# MMC register map
Vendor: Texas Instruments
Registers are 32-bit, access per field, reset 0x0 unless marked. A register's access mark holds for its fields unless they carry their own. Offsets are as the file gives them; [hi:lo] are bit positions; 'fields as' and 'values as' point back to an identical list.

## MMC (part 2 of 2)
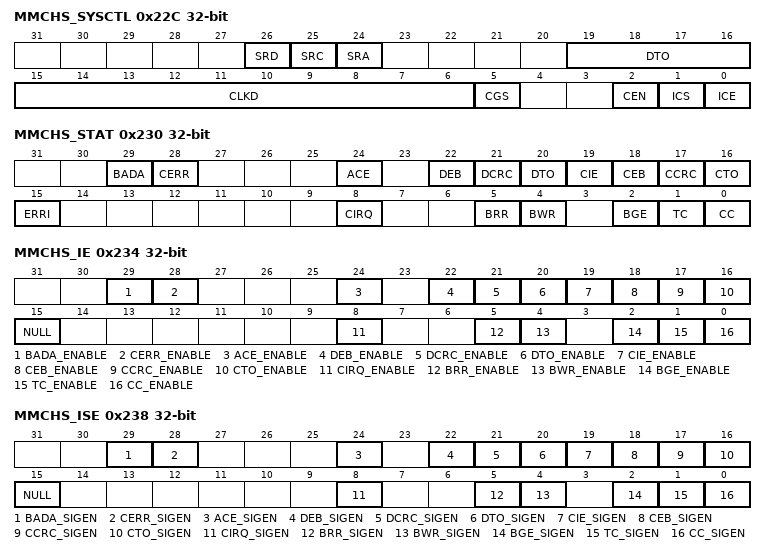
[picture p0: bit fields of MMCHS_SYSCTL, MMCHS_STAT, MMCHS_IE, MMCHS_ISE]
0x22C MMCHS_SYSCTL — SD System Control Register This register defines the system controls to set software resets, clock frequency management and data timeout. [31:24] = Software resets [23:16] = Timeout control [15:0] = Clock control
  [26] SRD rw — Software reset for DAT line This bit is set to 1 for reset and released to 0 when completed. For more information about SRD bit manipulation, see . DAT finite state machine in both clock domain are also reset. Here below are the registers cleared by MMCHS_SYSCTL[SRD]: - MMCHS_DATA - MMCHS_PSTATE: BRE, BWE, RTA, WTA, DLA and DATI - MMCHS_HCTL: SBGR and CR - MMCHS_STAT: BRR, BWR, BGE and TC Interconnect and SDIO buffer data management is reinitialized.
    0=Work (Reset completed); 1=Reset (Software reset for DAT line)
  [25] SRC rw — Software reset for CMD line For more information about SRC bit manipulation, see . This bit is set to 1 for reset and released to 0 when completed. CMD finite state machine in both clock domain are also reset. Here below the registers cleared by MMCHS_SYSCTL[SRC]: - MMCHS_PSTATE: CMDI - MMCHS_STAT: CC Interconnect and SDIO command status management is reinitialized.
    0=Work (Reset completed); 1=Reset (Software reset for CMD line)
  [24] SRA rw — Software reset for all This bit is set to 1 for reset , and released to 0 when completed. This reset affects the entire host controller except for the capabilities registers (MMCHS_CAPA and MMCHS_CUR_CAPA).
    0=Work (Reset completed); 1=Reset (Software reset for all the design)
  [19:16] DTO rw — Data timeout counter value and busy timeout. This value determines the interval by which DAT lines timeouts are detected. The host driver needs to set this bitfield based on - the maximum read access time (NAC) (Refer to the SD Specification Part1 Physical Layer), - the data read access time values (TAAC and NSAC) in the card specific data register (CSD) of the card, - the timeout clock base frequency (MMCHS_CAPA[TCF]). If the card does not respond within the specified number of cycles, a data timeout error occurs (MMCHS_STA[DTO]). The MMCHS_SYSCTL[DTO] register is also used to check busy duration, to generate busy timeout for commands with busy response or for busy programming during a write command. Timeout on CRC status is generated if no CRC token is present after a block write.
    0=1stDTO (TCF x 2^13); 1=2ndDTO (TCF x 2^14); 14=15thDTO (TCF x 2^27)
  [15:6] CLKD rw — Clock frequency select These bits define the ratio between MMC_FCLK and the output clock frequency on the mmc_clk pin.
    0=Div1023 (MMC_FCLK bypass); 1=Bypass0 (MMC_FCLK bypass); 2=Bypass1 (MMC_FCLK / 2); 3=Div3 (MMC_FCLK / 3); 0x3FF=Div2 (MMC_FCLK / 1023)
  [5] CGS ro — Clock Generator Select - For SD cards Host Controller Version 3.00 supports this bit. This bit is used to select the clock generator mode in MMCHS_SYSCTL[15:6] CLKD. If the Programmable Clock Mode is supported (non-zero value is set to MMCHS_CAPA2[23:16] CM), this bit attribute is RW, and if not supported, this bit attribute is RO and zero is read. This bit depends on the setting of MMCHS_AC12[31] PV_ENABLE. If PV_ENABLE = 0, this bit is set by Host Driver. If PV_ENABLE = 1, this bit is automatically set to a value specified in one of Preset Value registers, see, .
  [2] CEN rw — Clock enable This bit controls if the clock is provided to the card or not.
    0=Disable (The clock is not provided to the card . Clock frequency can be changed .); 1=Enable (The clock is provided to the card and can be automatically gated when[AUTOIDLE] is set to 1 (default value) . The host driver shall wait to set this bit to 1 until the Internal clock is stable ([ICS]).)
  [1] ICS ro — Internal clock stable (status) This bit indicates either the internal clock is stable or not.
    1=Ready (The internal clock is stable after enabling the clock ([ICE]) or after changing the clock ratio ([CLKD]).); 0=NotReady (The internal clock is not stable.)
  [0] ICE rw — Internal clock enable This register controls the internal clock activity. In very low power state, the internal clock is stopped. Note: The activity of the debounce clock (used for wakeup events) and the interface clock (used for reads and writes to the module register map) are not affected by this register.
    0=Stop (The internal clock is stopped (very low power state).); 1=Oscillate (The internal clock oscillates and can be automatically gated when[AUTOIDLE] is set to 1 (default value) .)
0x230 MMCHS_STAT — Interrupt Status Register The interrupt status regroups all the status of the module internal events that can generate an interrupt. [31:16] = Error Interrupt Status [15:0] = Normal Interrupt Status
  [29] BADA rw — Bad access to data space This bit is set automatically to indicate a bad access to buffer when not allowed: -This bit is set during a read access to the data register (MMCHS_DATA) while buffer reads are not allowed (MMCHS_PSTATE[BRE] =0) -This bit is set during a write access to the data register (MMCHS_DATA) while buffer writes are not allowed (MMCHS_STATE[BWE] =0)
    0=St_un_w (Status bit unchanged); 1=St_rst_w (Status is cleared); 1=IRQ_tru_r (Bad Access); 0=IRQ_fal_r (No Interrupt.)
  [28] CERR rw — Card error This bit is set automatically when there is at least one error in a response of type R1, R1b, R6, R5 or R5b. Only bits referenced as type E(error) in status field in the response can set a card status error. An error bit in the response is flagged only if corresponding bit in card status response error MMCHS_CSRE in set. There is no card error detection for autoCMD12 command. The host driver shall read MMCHS_RSP76 register to detect error bits in the command response.
    0=St_un_w (Status bit unchanged); 1=St_rst_w (Status is cleared); 1=IRQ_tru_r (Card error); 0=IRQ_fal_r (No Error)
  [24] ACE rw — Auto CMD error Auto CMD12 uses this error status. This bit is set when detecting that one of the bits D00-D04 in Auto CMD Error Status register (MMCHS_AC12) has changed from 0 to 1. In case of Auto CMD12, this bit is set to 1, not only when the errors in Auto CMD12 occur but also when Auto CMD12 is not executed due to the previous command error.
    0=St_un_w (Status bit unchanged); 1=St_rst_w (Status is cleared); 1=IRQ_tru_r (Auto CMD error); 0=IRQ_fal_r (No Error.)
  [22] DEB rw — Data End Bit error This bit is set automatically when detecting a 0 at the end bit position of read data on DAT line or at the end position of the CRC status in write mode.
    0=St_un_w (Status bit unchanged); 1=St_rst_w (Status is cleared); 1=IRQ_tru_r (Data end bit error); 0=IRQ_fal_r (No Error)
  [21] DCRC rw — Data CRC Error This bit is set automatically when there is a CRC16 error in the data phase response following a block read command or if there is a 3-bit CRC status different of a position '010' token during a block write command.
    0=St_un_w (Status bit unchanged); 1=St_rst_w (Status is cleared); 1=IRQ_tru_r (Data CRC error); 0=IRQ_fal_r (No Error.)
  [20] DTO rw — Data timeout error This bit is set automatically according to the following conditions: - busy timeout for R1b, R5b response type - busy timeout after write CRC status - write CRC status timeout - read data timeout
    0=St_un_w (Status bit unchanged); 1=St_rst_w (Status is cleared); 1=IRQ_tru_r (Time out); 0=IRQ_fal_r (No error.)
  [19] CIE rw — Command index error This bit is set automatically when response index differs from corresponding command index previously emitted. It depends on the enable in MMCHS_CMD[CICE] register.
    0=St_un_w (Status bit unchanged); 1=St_rst_w (Status is cleared); 1=IRQ_tru_r (Command index error); 0=IRQ_fal_r (No error.)
  [18] CEB rw — Command end bit error This bit is set automatically when detecting a 0 at the end bit position of a command response.
    0=St_un_w (Status bit unchanged); 1=St_rst_w (Status is cleared); 1=IRQ_tru_r (Command end bit error); 0=IRQ_fal_r (No error.)
  [17] CCRC rw — Command CRC Error This bit is set automatically when there is a CRC7 error in the command response depending on the enable in MMCHS_CMD[CCCE] register.
    0=St_un_w (Status bit unchanged); 1=St_rst_w (Status is cleared); 1=IRQ_tru_r (Command CRC error); 0=IRQ_fal_r (No Error.)
  [16] CTO rw — Command Timeout Error This bit is set automatically when no response is received within 64 clock cycles from the end bit of the command. For commands that reply within 5 clock cycles - the timeout is still detected at 64 clock cycles.
    0=St_un_w (Status bit unchanged); 1=St_rst_w (Status is cleared); 1=IRQ_tru_r (Time Out); 0=IRQ_fal_r (No error)
  [15] ERRI ro — Error Interrupt If any of the bits in the Error Interrupt Status register (MMCHS_STAT[31:16]) are set, then this bit is set to 1. Therefore the host driver can efficiently test for an error by checking this bit first. Writes to this bit are ignored.
    1=IRQ_tru_r (Error interrupt event(s) occurred); 0=IRQ_fal_r (No Interrupt.)
  [8] CIRQ ro — Card interrupt This bit is only used for SD and SDIO cards. In 1-bit mode, interrupt source is asynchronous (can be a source of asynchronous wakeup). In 4-bit mode, interrupt source is sampled during the interrupt cycle. The controller interrupt must be clear by setting MMCHS_IE[CIRQ] to 0, then the host driver must start the interrupt service with card (clearing card interrupt status) to remove card interrupt source. Otherwise the Controller interrupt will be reasserted as soon as MMCHS_IE[CIRQ] is set to 1. Writes to this bit are ignored.
    1=IRQ_tru_r (Generate card interrupt); 0=IRQ_fal_r (No card interrupt)
  [5] BRR rw — Buffer read ready This bit is set automatically during a read operation to the card (see class 2 - block oriented read commands) when one block specified by MMCHS_BLK[BLEN] is completely written in the buffer. It indicates that the memory card has filled out the buffer and that the local host needs to empty the buffer by reading it. Note: If the DMA receive-mode is enabled, this bit is never set; instead a DMA receive request to the main DMA controller of the system is generated.
    0=St_un_w (Status bit unchanged); 1=St_rst_w (Status is cleared); 1=IRQ_tru_r (Ready to read buffer); 0=IRQ_fal_r (Not Ready to read buffer)
  [4] BWR rw — Buffer write ready This bit is set automatically during a write operation to the card (see class 4 - block oriented write command) when the host can write a complete block as specified by MMCHS_BLK[BLEN]. It indicates that the memory card has emptied one block from the buffer and that the local host is able to write one block of data into the buffer. Note: If the DMA transmit mode is enabled, this bit is never set; instead, a DMA transmit request to the main DMA controller of the system is generated.
    0=St_un_w (Status bit unchanged); 1=St_rst_w (Status is cleared); 1=IRQ_tru_r (Ready to write buffer); 0=IRQ_fal_r (Not Ready to write buffer)
  [2] BGE rw — Block gap event When a stop at block gap is requested (MMCHS_HCTL[SBGR]), this bit is automatically set when transaction is stopped at the block gap during a read or write operation. This event does not occur when the stop at block gap is requested on the last block. In read mode, a 1-to-0 transition of the DAT Line active status (MMCHS_PSTATE[DLA]) between data blocks generates a Block gap event interrupt.
    0=St_un_w (Status bit unchanged); 1=St_rst_w (Status is cleared); 1=IRQ_tru_r (Transaction stopped at block gap); 0=IRQ_fal_r (No block gap event)
  [1] TC rw — Transfer completed This bit is always set when a read/write transfer is completed or between two blocks when the transfer is stopped due to a stop at block gap request (MMCHS_HCTL[SBGR]). In Read mode: This bit is automatically set on completion of a read transfer (MMCHS_PSTATE[RTA]). In write mode: This bit is set automatically on completion of the DAT line use (MMCHS_PSTATE[DLA]).
    0=St_un_w (Status bit unchanged); 1=St_rst_w (Status is cleared); 1=IRQ_tru_r (Data transfer complete); 0=IRQ_fal_r (No transfer complete)
  [0] CC rw — Command complete This bit is set when a 1-to-0 transition occurs in the register command inhibit (MMCHS_PSTATE[CMDI]) If the command is a type for which no response is expected, then the command complete interrupt is generated at the end of the command. A command timeout error (MMCHS_STAT[CTO]) has higher priority than command complete (MMCHS_STAT[CC]). If a response is expected but none is received, then a command timeout error is detected and signaled instead of the command complete interrupt.
    0=St_un_w (Status bit unchanged); 1=St_rst_w (Status is cleared); 1=IRQ_tru_r (Command complete); 0=IRQ_fal_r (No Command complete)
0x234 MMCHS_IE — Interrupt Status Enable Register This register allows to enable/disable the module to set status bits, on an event-by-event basis. [31:16] = Error Interrupt Status Enable [15:0] = Normal Interrupt Status Enable
  [29] BADA_ENABLE rw — Bad access to data space Status Enable
    0=Masked; 1=Enabled
  [28] CERR_ENABLE rw — Card Error Status Enable
    0=Masked; 1=Enabled
  [24] ACE_ENABLE rw — Auto CMD Error Status Enable
    0=Masked; 1=Enabled
  [22] DEB_ENABLE rw — Data End Bit Error Status Enable
    0=Masked; 1=Enabled
  [21] DCRC_ENABLE rw — Data CRC Error Status Enable
    0=Masked; 1=Enabled
  [20] DTO_ENABLE rw — Data Timeout Error Status Enable
    0=Masked (The data timeout detection is deactivated. The host controller provides the clock to the card until the card sends the data or the transfer is aborted.); 1=Enabled (The data timeout detection is enabled.)
  [19] CIE_ENABLE rw — Command Index Error Status Enable
    0=Masked; 1=Enabled
  [18] CEB_ENABLE rw — Command End Bit Error Status Enable
    0=Masked; 1=Enabled
  [17] CCRC_ENABLE rw — Command CRC Error Status Enable
    0=Masked; 1=Enabled
  [16] CTO_ENABLE rw — Command Timeout Error Status Enable
    0=Masked; 1=Enabled
  [15] NULL ro — Fixed to 0 The host driver shall control error interrupts using the Error Interrupt Signal Enable register. Writes to this bit are ignored
  [8] CIRQ_ENABLE rw — Card Status Enable A clear of this bit also clears the corresponding status bit. During 1-bit mode, if the interrupt routine doesn't remove the source of a card interrupt in the SDIO card, the status bit is reasserted when this bit is set to 1.
    0=Masked; 1=Enabled
  [5] BRR_ENABLE rw — Buffer Read Ready Status Enable
    0=Masked; 1=Enabled
  [4] BWR_ENABLE rw — Buffer Write Ready Status Enable
    0=Masked; 1=Enabled
  [2] BGE_ENABLE rw — Block Gap Event Status Enable
    0=Masked; 1=Enabled
  [1] TC_ENABLE rw — Transfer Complete Status Enable
    0=Masked; 1=Enabled
  [0] CC_ENABLE rw — Command Complete Status Enable
    0=Masked; 1=Enabled
0x238 MMCHS_ISE — Interrupt Signal Enable Register This register allows to enable/disable the module internal sources of status, on an event-by-event basis. [31:16] = Error Interrupt Signal Enable [15:0] = Normal Interrupt Signal Enable
  [29] BADA_SIGEN rw — Bad access to data space Signal Enable
    0=Masked; 1=Enabled
  [28] CERR_SIGEN rw — Card Error Interrupt Signal Enable
    0=Masked; 1=Enabled
  [24] ACE_SIGEN rw — Auto CMD Error Signal Enable
    0=Masked; 1=Enabled
  [22] DEB_SIGEN rw — Data End Bit Error Signal Enable
    0=Masked; 1=Enabled
  [21] DCRC_SIGEN rw — Data CRC Error Signal Enable
    0=Masked; 1=Enabled
  [20] DTO_SIGEN rw — Data Timeout Error Signal Enable
    0=Masked; 1=Enabled
  [19] CIE_SIGEN rw — Command Index Error Signal Enable
    0=Masked; 1=Enabled
  [18] CEB_SIGEN rw — Command End Bit Error Signal Enable
    0=Masked; 1=Enabled
  [17] CCRC_SIGEN rw — Command CRC Error Signal Enable
    0=Masked; 1=Enabled
  [16] CTO_SIGEN rw — Command timeout Error Signal Enable
    0=Masked; 1=Enabled
  [15] NULL ro — Fixed to 0 The host driver shall control error interrupts using the Error Interrupt Signal Enable register. Writes to this bit are ignored
  [8] CIRQ_SIGEN rw — Card Interrupt Signal Enable
    0=Masked; 1=Enabled
  [5] BRR_SIGEN rw — Buffer Read Ready Signal Enable
    0=Masked; 1=Enabled
  [4] BWR_SIGEN rw — Buffer Write Ready Signal Enable
    0=Masked; 1=Enabled
  [2] BGE_SIGEN rw — Black Gap Event Signal Enable
    0=Masked; 1=Enabled
  [1] TC_SIGEN rw — Transfer Completed Status Enable
    0=Masked; 1=Enabled
  [0] CC_SIGEN rw — Command Complete Status Enable
    0=Masked; 1=Enabled
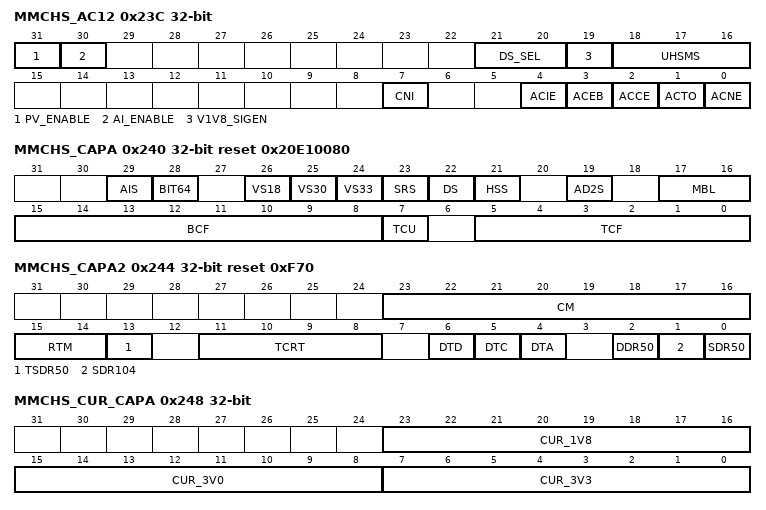
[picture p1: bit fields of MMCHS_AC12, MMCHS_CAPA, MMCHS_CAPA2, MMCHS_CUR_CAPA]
0x23C MMCHS_AC12 — Host Control 2 Register and Auto CMD Error Status Register This register is used to indicate CMD12 response error of Auto CMD12. The Host driver can determine what kind of Auto CMD12 errors occur by this register. Bits[7:0] are valid only when the [3:2] ACEN bitfield is configured to enable Auto CMD and the Auto CMD Error bit ([24]ACE) is set.
  [31] PV_ENABLE rw — Preset Value Enable Host Controller Version 3.00 supports this bit. As the operating SDCLK frequency and I/O driver strength depend on the Host System implementation, it is difficult to determine these parameters in the Standard Host Driver. When Preset Value Enable is set, automatic SDCLK frequency generation and driver strength selection is performed without considering system specific conditions. This bit enables the functions defined in the Preset Value registers, see, . If this bit is set to 0, MMCHS_SYSCTL[15:6] CLKD, MMCHS_SYSCTL[5] CGS and MMCHS_AC12[21:20] DS_SEL are set by Host Driver. If this bit is set to 1, MMCHS_SYSCTL[15:6] CLKD, MMCHS_SYSCTL[5] CGS and MMCHS_AC12[21:20] DS_SEL are set by Host Controller as specified in the Preset Value registers, see, .
    0=Disabled (SDCLK and Driver Strength (DS_SEL) are controlled by Host Driver.); 1=Enabled (Automatic Selection by Preset Value are Enabled.)
  [30] AI_ENABLE rw — Asynchronous Interrupt Enable This bit can be set to 1 if a card supports asynchronous interrupts and MMCHS_CAPA[29] AIS is set to 1. Asynchronous interrupt is effective when DAT[1] interrupt is used in 4-bit SD mode (and zero is set to Interrupt Pin Select in the Shared Bus Control register). If this bit is set to 1, the Host Driver can stop the SDCLK during asynchronous interrupt period to save power. During this period, the Host Controller continues to deliver the Card Interrupt to the host when it is asserted by the Card.
    0=Disabled; 1=Enabled
  [21:20] DS_SEL rw — Driver Strength Select Host Controller output driver in 1.8V signaling is selected by this bit. In 3.3V signaling, this field is not effective. This field can be set depending on Driver Type A, C and D support bits (DTA, DTC and DTD respectively) in the MMCHS_CAPA2 register. This bit depends on setting of Preset Value Enable. If Preset Value Enable = 0, this field is set by Host Driver. If Preset Value Enable = 1, this field is automatically set by a value specified in the one of Preset Value registers, see, .
    0=DTB (Driver Type B is selected (Default)); 1=DTA (Driver Type A is selected); 3=DTD (Driver Type D is selected); 2=DTC (Driver Type C is selected)
  [19] V1V8_SIGEN rw — 1.8V Signaling Enable This bit controls voltage regulator for I/O cell. 3.3V is supplied to the card regardless of signaling voltage. Setting this bit from 0 to 1 starts changing signal voltage from 3.3V to 1.8V. 1.8V regulator output shall be stable within 5ms. Host Controller clears this bit if switching to 1.8V signaling fails. Clearing this bit from 1 to 0 starts changing signal voltage from 1.8V to 3.3V. 3.3V regulator output shall be stable within 5ms. Host Driver can set this bit to 1 when Host Controller supports 1.8V signaling (One of support bits is set to 1: SDR50, SDR104 or DDR50 in MMCHS_CAPA2 register) and the card or device supports UHS-I (S18A=1. Refer to Bus Signal Voltage Switch Sequence in the Physical Layer Specification Version 3.0x).
    0=3V3 (3.3V Signaling); 1=1V8 (1.8V Signaling)
  [18:16] UHSMS rw — UHS Mode Select This field is used to select one of UHS-I modes and effective when 1.8V Signaling Enable is set to 1. If MMCHS_AC12[31] PV_ENABLE is set to 1, Host Controller sets MMCHS_SYSCTL[15:6] CLKD, MMCHS_SYSCTL[5] CGS and MMCHS_AC12[21:20] DS_SEL according to Preset Value registers, see, . In this case, one of preset value registers is selected by this field. Host Driver needs to reset MMCHS_SYSCTL[2] CEN before changing this field to avoid generating clock glitch. After setting this field, Host Driver sets MMCHS_SYSCTL[2] CEN again.0x2 to 0x7: Reserved .
    0=SDR12; 1=SDR25
  [7] CNI ro — Command Not Issued By Auto CMD12 Error Setting this bit to 1 means CMD_wo_DAT is not executed due to an Auto CMD12 Error (D04-D01) in this register.
    1=CmdNI (Command not issued); 0=No error
  [4] ACIE ro — Auto CMD Index Error for Auto CMD12 This bit is set if the Command Index error occurs in response to a command.
    1=Err (Error); 0=No error
  [3] ACEB ro — Auto CMD End Bit Error for Auto CMD12 This bit is set when detecting that the end bit of command response is 0.
    1=Err (End bit Error Generated); 0=No error
  [2] ACCE ro — Auto CMD CRC Error for Auto CMD12 This bit is set when detecting a CRC error in the command response.
    1=Err (CRC Error Generated); 0=No error
  [1] ACTO ro — Auto CMD Timeout Error for Auto CMD12 This bit is set if no response is returned within 64 SDCLK cycles from the end bit of command. If this bit is set to1, the other error status bits (D04-D02) are meaningless.
    1=TimeOut (Auto CMD Time Out); 0=No error
  [0] ACNE ro — Auto CMD12 Not Executed If memory multiple block data transfer is not started due to command error, this bit is not set because it is not necessary to issue Auto CMD12. Setting this bit to 1 means the Host Controller cannot issue Auto CMD12 to stop memory multiple block data transfer due to some error. If this bit is set to 1, other error status bits (D04-D01) are meaningless.
    1=NotExe (Auto CMD12 Not Executed); 0=Exe (Auto CMD12 Executed)
0x240 MMCHS_CAPA reset 0x20E10080 — Capabilities Register This register lists the capabilities of the SDIO host controller.
  [29] AIS ro — Asynchronous Interrupt Support Refer to SDIO Specification Version 3.00 about asynchronous interrupt.
    1=AIS_Sup (Asynchronous Interrupt Supported); 0=AIS_NotSup (Asynchronous Interrupt Not Supported)
  [28] BIT64 ro — 64 Bit System Bus Support Setting 1 to this bit indicates that the Host Controller supports 64-bit address descriptor mode and is connected to 64-bit address system bus.
    1=SysAddr64b (64 bit System bus address); 0=SysAddr32b (32 bit System bus address)
  [26] VS18 rw — Voltage support 1.8V Initialization of this register (via a write access to this register) depends on the system capabilities. The host driver shall not modify this register after the initilaization. This register is only reinitialized by a hard reset (via RESETN signal)
    0=St_1V8NotSup_w (1.8V Not supported); 1=St_1V8Sup_w (1.8V Supported); 1=1V8_Sup_r (1.8V Supported); 0=1V8_NotSup_r (1.8V Not Supported)
  [25] VS30 rw — Voltage support 3.0V Initialization of this register (via a write access to this register) depends on the system capabilities. The host driver shall not modify this register after the initilaization. This register is only reinitialized by a hard reset (via RESETN signal)
    0=St_3V0NotSup_w (3.0V Not supported); 1=St_3V0Sup_w (3.0V Supported); 1=3V0_Sup_r (3.0V Supported); 0=3V0_NotSup_r (3.0V Not Supported)
  [24] VS33 rw — Voltage support 3.3V Initialization of this register (via a write access to this register) depends on the system capabilities. The host driver shall not modify this register after the initilaization. This register is only reinitialized by a hard reset (via RESETN signal)
    0=St_3V3NotSup_w (3.3V Not supported); 1=St_3V3Sup_w (3.3V Supported); 1=3V3_Sup_r (3.3V Supported); 0=3V3_NotSup_r (3.3V Not Supported)
  [23] SRS ro — Suspend/Resume support (SDIO cards only) This bit indicates whether the host controller supports Suspend/Resume functionality.
    1=Supported (The Host controller supports Suspend/Resume functionality.); 0=NotSupported (The Host controller does not Suspend/Resume functionality.)
  [22] DS ro — DMA support This bit indicates that the Host Controller is able to use DMA to transfer data between system memory and the Host Controller directly.
    1=Supported (DMA Supported); 0=NotSupported (DMA Not Supported)
  [21] HSS ro — High speed support This bit indicates that the host controller supports high speed operations and can supply an up-to maximum card frequency.
    1=Supported (High Speed Supported); 0=NotSupported (High Speed Not Supported)
  [19] AD2S ro — ADMA2 Support This bit indicates whether the Host Controller is capable of using ADMA2. It depends on setting of generic parameter MADMA_EN
    1=ADMA2Supported; 0=ADMA2NotSupported
  [17:16] MBL ro — Maximum block length This value indicates the maximum block size that the host driver can read and write to the buffer in the host controller. This value depends on definition of generic parameter with a max value of 2048 bytes. The host controller supports 512 bytes and 1024 bytes block transfers.
    2=MBL_2_r (2048 bytes); 1=MBL_1_r (1024 bytes); 0=MBL_0_r (512 bytes)
  [15:8] BCF ro — Base Clock Frequency For SD Clock This value indicates the base (maximum) clock frequency for the SD Clock. 8-bit Base Clock Frequency This mode is supported by the Host Controller Version 3.00. Unit values are 1MHz. The supported clock range is 10MHz to 255MHz. FFh : 255MHz .... : ....... 02h : 2MHz 01h : 1MHz 00h : Get information via another method If the real frequency is 16.5MHz, the lager value shall be set 0001 0001b (17MHz) because the Host Driver use this value to calculate the clock divider value (Refer to MMCHS_SYSCTL[15:6] CLKD) and it shall not exceed upper limit of the SD Clock frequency. If these bits are all 0, the Host System has to get information via another method.
    0=OMeth (The value indicating the base (maximum) frequency for the output clock provided to the card is system dependent and is not available in this register. Get the information via another method.)
  [7] TCU ro — Timeout clock unit This bit shows the unit of base clock frequency used to detect Data Timeout Error (MMCHS_STAT[DTO]).
    1=KHz (MHz); 0=MHz (KHz)
  [5:0] TCF ro — Timeout clock frequency The timeout clock frequency is used to detect Data Timeout Error (MMCHS_STAT[DTO]).
    0=OMeth (The timeout clock frequency depends on the frequency of the clock provided to the card. The value of the timeout clock frequency is not available in this register.)
0x244 MMCHS_CAPA2 ro reset 0xF70 — Capabilities 2 Register This register provides the Host Driver with information specific to the Host Controller implementation. The Host Controller may implement these values as fixed or loaded from flash memory during power on initialization. Refer to Software Reset For All in the Software Reset register for loading from flash memory and completion timing control.
  [23:16] CM — Clock Multiplier This field indicates clock multiplier value of programmable clock generator. Refer to MMCHS_SYSCTL [15:0]. Setting 00h means that Host Controller does not support programmable clock generator. 00h : Clock Multiplier is Not Supported 01h : Clock Multiplier M = 2 02h : Clock Multiplier M = 3 .... : ...................... FFh : Clock Multiplier M = 256
  [15:14] RTM — Re-Tuning Modes This field selects re-tuning method and limits the maximum data length. Bit47-46 Re-Tuning Mode Re-Tuning Method Data Length There are two re-tuning timings: Re-Tuning Request controlled by the Host Controller and expiration of a Re-Tuning Timer controlled by the Host Driver. By receiving either timing, the Host Driver executes the re-tuning procedure just before a next command issue. The maximum data length per read/write command is restricted so that re-tuning procedures can be inserted during data transfers. (1) Re-Tuning Mode 1 The host controller does not have any internal logic to detect when the re-tuning needs to be performed. In this case, the Host Driver should maintain all re-tuning timings by using a Re-Tuning Timer. To enable inserting the re-tuning procedure during data transfers, the data length per read/write command shall be limited up to 4 MiB. (2) Re-Tuning Mode 2 The host controller has the capability to indicate the re-tuning timing by Re-Tuning Request during data transfers. Then the data length per read/write command shall be limited up to 4 MiB. During non data transfer, re-tuning timing is determined by either Re-Tuning Request or Re-Tuning Timer. If Re-Tuning Request is used, Re-Tuning Timer should be disabled. (3) Re-Tuning Mode 3 The host controller has the capability to take care of the re-tuning during data transfer (Auto Re-Tuning). Re-Tuning Request shall not be generated during data transfers and there is no limitation to data length per read/write command. During non data transfer, re-tuning timing is determined by either Re-Tuning Request or Re-Tuning Timer. If Re-Tuning Request is used, Re-Tuning Timer should be disabled. Re-Tuning Timer Control Example for Re-Tuning Mode 1 The initial value of re-tuning timer is provided by Timer Count for Re-Tuning field in this register. The timer starts counting by loading the initial value. When the timer expires, the Host Driver marks an expiration flag. On receiving a command request, the Host driver checks the expiration flag. If the expiration flag is set, then the Host Driver should perform the re-tuning procedure before issuing a command. If the expiration flag is not set, then the Host Driver issues a command without performing the re-tuning procedure. Every time the re-tuning procedure is performed, the timer loads the new initial value and the expiration flag is cleared. Re-Tuning Timer Control Example for Re-Tuning Mode 2 and Mode 3 The timer control is almost the same as Re-Tuning Mode 1 except the timer loads the new initial value after data transfer (when receiving Transfer Complete). In case of Mode 3, Timer Count for Re-Tuning is set either smaller value: Tuning effective time after re-tuning procedure or after data transfer. If a Host System goes into power down mode, the Host Driver should stop the re-tuning timer and set the expiration flag to 1 when the Host System resumes from power down mode.
    2=Mode3 (Auto Re-Tuning (for transfer) - Timer and Re-Tuning Request); 1=Mode2 (Timer and Re-Tuning Request - Max data length 4 MiB); 0=Mode1 (Timer - Max data length 4 MiB)
  [13] TSDR50 — Use Tuning for SDR50 If this bit is set to 1, this Host Controller requires tuning to operate SDR50.
    1=Required (SDR50 requires tuning.); 0=NotRequired (SDR50 does not require tuning.)
  [11:8] TCRT — Timer Count for Re-Tuning This field indicates an initial value of the Re-Tuning Timer for Re-Tuning Mode 1 to 3. Setting to 0 disables Re-Tuning Timer.
    3=TCRT_3_r (4 seconds); 4=TCRT_4_r (8 seconds); 11=TCRT_11_r (1024 seconds); 15=OtherSource (Get information from other source); 2=TCRT_2_r (2 seconds); 0=Disabled (Re-Tuning Timer disabled); 10=TCRT_10_r (512 seconds); 6=TCRT_6_r (32 seconds); 1=TCRT_1_r (1 second); 8=TCRT_8_r (128 seconds); 7=TCRT_7_r (64 seconds); 9=TCRT_9_r (256 seconds); 5=TCRT_5_r (16 seconds)
  [6] DTD — Driver Type D Support This bit indicates support of Driver Type D for 1.8 Signaling.
    1=Supported (Driver Type D is Supported); 0=NotSupported (Driver Type D is Not Supported.)
  [5] DTC — Driver Type C Support This bit indicates support of Driver Type C for 1.8 Signaling.
    1=Supported (Driver Type C is Supported.); 0=NotSupported (Driver Type C is Not Supported.)
  [4] DTA — Driver Type A Support This bit indicates support of Driver Type A for 1.8 Signaling.
    1=Supported (Driver Type A is Supported.); 0=NotSupported (Driver Type A is Not Supported.)
  [2] DDR50 — DDR50 Support
    1=Supported (DDR50 is Supported.); 0=NotSupported (DDR50 is Not Supported.)
  [1] SDR104 — SDR104 Support
    1=Supported (SDR104 is Supported.); 0=NotSupported (SDR104 is Not Supported.)
  [0] SDR50 — SDR50 Support If SDR104 is supported, this bit shall be set to 1. Bit 13 indicates whether SDR50 requires tuning or not.
    1=Supported (SDR50 is Supported.); 0=NotSupported (SDR50 is Not Supported.)
0x248 MMCHS_CUR_CAPA — Maximum Current Capabilities Register This register indicates the maximum current capability for each voltage. The value is meaningful if the voltage support is set in the capabilities register (). Initialization of this register (via a write access to this register) depends on the system capabilities. The host driver shall not modify this register after the initilaization. This register is only reinitialized by a hard reset (via RESETN signal)
  [all] fields
    0=OMeth (The maximum current capability for this voltage is not available. Feature not implemented.)
  [23:16] CUR_1V8 rw — Maximum current for 1.8V
  [15:8] CUR_3V0 rw — Maximum current for 3.0V
  [7:0] CUR_3V3 rw — Maximum current for 3.3V
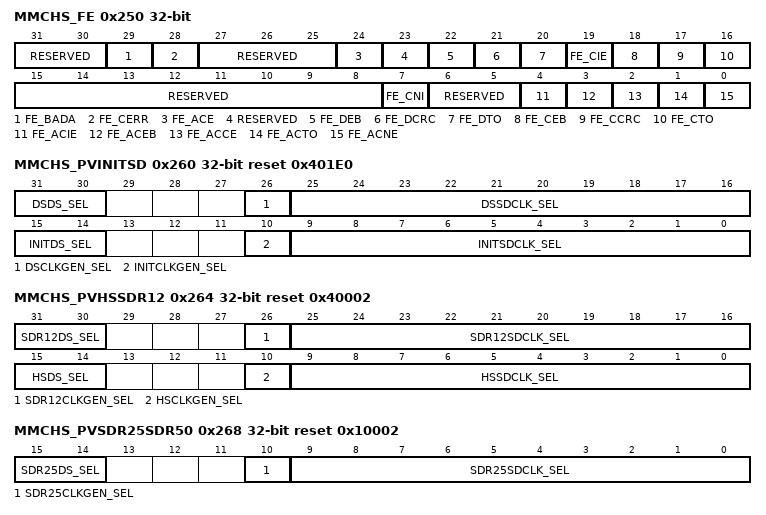
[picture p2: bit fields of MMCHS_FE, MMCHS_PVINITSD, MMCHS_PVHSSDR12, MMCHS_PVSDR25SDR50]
0x250 MMCHS_FE access not given — Force Event Register for Auto CMD Error Status and Error Interrupt status The Force Event Register is not a physically implemented register. Rather, it is an address at which the Auto CMD Error Status Register () can be written. Writing 1 : set each bit of the Auto CMD Error Status Register Writing 0 : no effect Rather, it is an address at which the Error Interrupt Status register can be written. The effect of a write to this address will be reflected in the Error Interrupt Status Register if the corresponding bit of the Error Interrupt Status Enable Register is set. Writing 1 : set each bit of the Error Interrupt Status Register Writing 0 : no effect Note: By setting this register, the Error Interrupt can be set in the Error Interrupt Status register. In order to generate interrupt signal, both the Error Interrupt Status Enable and Error Interrupt Signal Enable shall be set.
  [31:30] RESERVED — (access NA)
  [29] FE_BADA wo — Force Event Bad access to data space.
    0=NoAction (No effect, No Interrupt.); 1=IntForced (Interrupt Forced)
  [28] FE_CERR wo — Force Event Card error.
    values as FE_BADA
  [27:25] RESERVED — (access NA)
  [24] FE_ACE wo — Force Event for Auto CMD Error - For Auto CMD12
    values as FE_BADA
  [23] RESERVED — (access NA)
  [22] FE_DEB wo — Force Event Data End Bit error.
    values as FE_BADA
  [21] FE_DCRC wo — Force Event Data CRC Error.
    values as FE_BADA
  [20] FE_DTO wo — Force Event Data Timeout Error.
    values as FE_BADA
  [19] FE_CIE wo — Force Event Command Index Error.
    values as FE_BADA
  [18] FE_CEB wo — Force Event Command End Bit Error.
    values as FE_BADA
  [17] FE_CCRC wo — Force Event Command CRC Error.
    values as FE_BADA
  [16] FE_CTO wo — Command Timeout Error This bit is set automatically when no response is received within 64 clock cycles from the end bit of the command. For commands that reply within 5 clock cycles - the timeout is still detected at 64 clock cycles.
    0=St_un_w (Status bit unchanged); 1=St_rst_w (Status is cleared)
  [15:8] RESERVED — (access NA)
  [7] FE_CNI wo — Force Event Command not issued by Auto CMD12 error
    values as FE_BADA
  [6:5] RESERVED — (access NA)
  [4] FE_ACIE wo — Force Event for Auto CMD Index Error - For Auto CMD12
    values as FE_BADA
  [3] FE_ACEB wo — Force Event Auto CMD End Bit Error
    values as FE_BADA
  [2] FE_ACCE wo — Force Event Auto CMD CRC Error
    values as FE_BADA
  [1] FE_ACTO wo — Force Event Auto CMD Timeout Error
    values as FE_BADA
  [0] FE_ACNE wo — Force Event Auto CMD12 Not Executed
    values as FE_BADA
0x260 MMCHS_PVINITSD ro reset 0x401E0 — Preset Value for Initialization and Default Speed modes
  [31:30] DSDS_SEL — Driver Strength Select Value - Default Speed mode Driver Strength is supported by 1.8V signaling bus speed modes. This field is meaningless for 3.3V signaling.
    3=DTD (Driver Type D is Selected.); 2=DTC (Driver Type C is Selected.); 1=DTA (Driver Type A is Selected.); 0=DTB (Driver Type B is Selected.)
  [26] DSCLKGEN_SEL — Clock Generator Select Value - Default Speed mode This bit is effective when Host Controller supports programmable clock generator.
    1=Programmable Clock Generator; 0=Host Controller Ver2.00 Compatible Clock Generator
  [25:16] DSSDCLK_SEL — SDCLK Frequency Select Value - Default Speed mode 10-bit preset value to set MMCHS_SYSCTL[15:6] CLKD is described by a host system.
  [15:14] INITDS_SEL — Driver Strength Select Value - Initialization mode Driver Strength is supported by 1.8V signaling bus speed modes. This field is meaningless for 3.3V signaling.
    3=DTD (Driver Type D is Selected); 2=DTC (Driver Type C is Selected); 1=DTA (Driver Type A is Selected); 0=DTB (Driver Type B is Selected)
  [10] INITCLKGEN_SEL — Clock Generator Select Value - Initialization mode This bit is effective when Host Controller supports programmable clock generator.
    values as DSCLKGEN_SEL
  [9:0] INITSDCLK_SEL — SDCLK Frequency Select Value - Initialization mode 10-bit preset value to set MMCHS_SYSCTL[15:6] CLKD is described by a host system.
0x264 MMCHS_PVHSSDR12 ro reset 0x40002 — Preset Value for High Speed and SDR12 speed modes
  [31:30] SDR12DS_SEL — Driver Strength Select Value - SDR12 mode Driver Strength is supported by 1.8V signaling bus speed modes. This field is meaningless for 3.3V signaling.
    values as MMCHS_PVINITSD.DSDS_SEL
  [26] SDR12CLKGEN_SEL — Clock Generator Select Value - SDR12 mode This bit is effective when Host Controller supports programmable clock generator.
    values as MMCHS_PVINITSD.DSCLKGEN_SEL
  [25:16] SDR12SDCLK_SEL — SDCLK Frequency Select Value - SDR12 mode 10-bit preset value to set MMCHS_SYSCTL[15:6] CLKD is described by a host system.
  [15:14] HSDS_SEL — Driver Strength Select Value - High Speed mode Driver Strength is supported by 1.8V signaling bus speed modes. This field is meaningless for 3.3V signaling.
    values as MMCHS_PVINITSD.DSDS_SEL
  [10] HSCLKGEN_SEL — Clock Generator Select Value - High Speed mode This bit is effective when Host Controller supports programmable clock generator.
    values as MMCHS_PVINITSD.DSCLKGEN_SEL
  [9:0] HSSDCLK_SEL — SDCLK Frequency Select Value - High Speed mode 10-bit preset value to set MMCHS_SYSCTL[15:6] CLKD is described by a host system.
0x268 MMCHS_PVSDR25SDR50 ro reset 0x10002 — Preset Value for SDR25 speed mode
  [15:14] SDR25DS_SEL — Driver Strength Select Value - SDR25 mode Driver Strength is supported by 1.8V signaling bus speed modes. This field is meaningless for 3.3V signaling.
    values as MMCHS_PVINITSD.DSDS_SEL
  [10] SDR25CLKGEN_SEL — Clock Generator Select Value - SDR25 mode This bit is effective when Host Controller supports programmable clock generator.
    1=Programmable Clock Generato; 0=Host Controller Ver2.00 Compatible Clock Generator
  [9:0] SDR25SDCLK_SEL — SDCLK Frequency Select Value - SDR25 mode 10-bit preset value to set MMCHS_SYSCTL[15:6] CLKD is described by a host system.
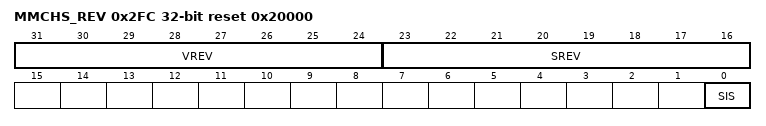
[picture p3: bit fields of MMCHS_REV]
0x2FC MMCHS_REV ro reset 0x20000 (reset mask 0xFFFFFF) — Versions Register This register contains the hard coded RTL vendor revision number, the version number of SD specification compliancy and a slot status bit. [31:16] = Host controller version [15:0] = Slot Interrupt Status
  [31:24] VREV — Vendor Version Number: IP revision [7:4] Major revision [3:0] Minor revision Examples: 0x10 for 1.0 0x21 for 2.1
  [23:16] SREV — Specification Version Number This status indicates the Host Controller Spec. Version. The upper and lower 4-bits indicate the version.
    3=Other (Reserved); 2=Ver3 (SD Host Specification Version 3.00.); 1=Ver2 (SD Host Specification Version 2.00 - Including the feature of the ADMA and Test Register.); 0=Ver1 (SD Host Specification Version 1.00.)
  [0] SIS — Slot Interrupt Status This status bit indicates the inverted state of interrupt signal for the module. By a power on reset or by setting a software reset for all (MMCHS_HCTL[SRA]), the interrupt signal shall be de-asserted and this status shall read 0.
